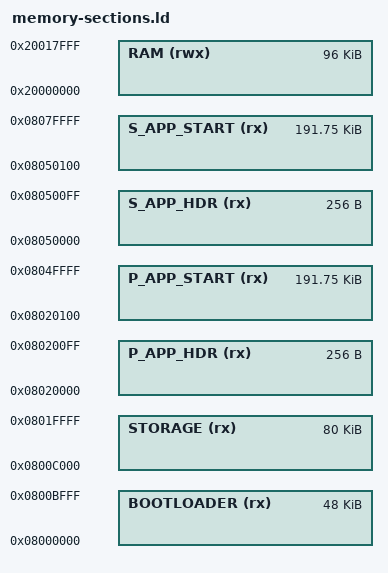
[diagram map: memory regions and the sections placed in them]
/* stm32F401re Memory Layout */
MEMORY
{
  BOOTLOADER (rx) : ORIGIN = 0x08000000, LENGTH = 0xC000
  STORAGE (rx) : ORIGIN = 0x0800C000, LENGTH = 0x14000
  P_APP_HDR (rx) : ORIGIN = 0x08020000, LENGTH = 0x100
  P_APP_START (rx) : ORIGIN = ORIGIN(P_APP_HDR) + LENGTH(P_APP_HDR) , LENGTH = 0x30000 - 0x100
  S_APP_HDR (rx) : ORIGIN = 0x08050000, LENGTH = 0x100
  S_APP_START (rx) : ORIGIN = ORIGIN(S_APP_HDR) + LENGTH(S_APP_HDR), LENGTH = 0x30000 - 0x100
  RAM (rwx) :  ORIGIN = 0x20000000, LENGTH = 96K
}
